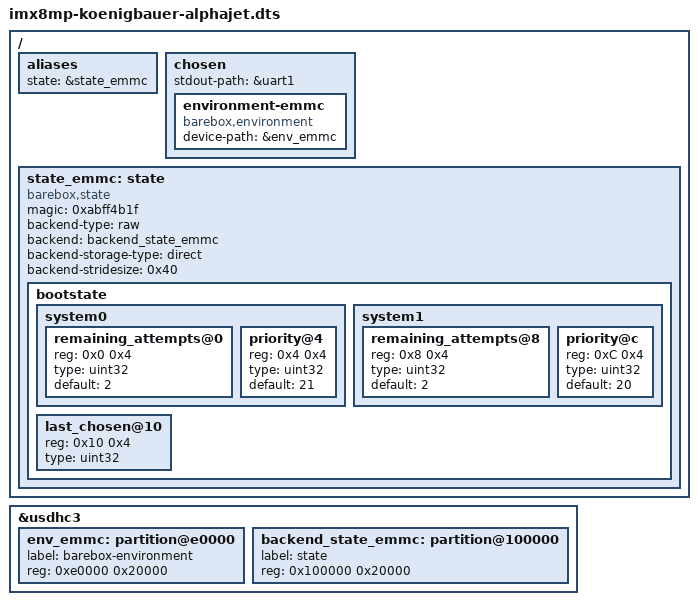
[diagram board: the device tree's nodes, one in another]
// SPDX-License-Identifier: (GPL-2.0+ OR MIT)
// SPDX-FileCopyrightText: 2023 Pengutronix, Johannes Zink <j.zink@pengutronix.de>

#include "imx8mp-koenigbauer-alphajet.kernel.dts"
#include "imx8mp-congatec-qmx8p.dtsi"

/ {
	aliases {
		state = &state_emmc;
	};

	chosen {
		stdout-path = &uart1; /* baseboard UART0, connector J12 */
		environment-emmc {
			compatible = "barebox,environment";
			device-path = &env_emmc;
		};
	};

	state_emmc: state {
		compatible = "barebox,state";
		magic = <0xabff4b1f>;
		backend-type = "raw";
		backend = <&backend_state_emmc>;
		backend-storage-type="direct";
		backend-stridesize = <0x40>;
		#address-cells = <1>;
		#size-cells = <1>;

		bootstate {
			#address-cells = <1>;
			#size-cells = <1>;

			system0 {
				#address-cells = <1>;
				#size-cells = <1>;

				remaining_attempts@0 {
					reg = <0x0 0x4>;
					type = "uint32";
					default = <2>;
				};

				priority@4 {
					reg = <0x4 0x4>;
					type= "uint32";
					default = <21>;
				};
			};

			system1 {
				#address-cells = <1>;
				#size-cells = <1>;

				remaining_attempts@8 {
					reg = <0x8 0x4>;
					type = "uint32";
					default = <2>;
				};

				priority@c {
					reg = <0xC 0x4>;
					type= "uint32";
					default = <20>;
				};
			};

			last_chosen@10 {
				reg = <0x10 0x4>;
				type = "uint32";
			};

		};

	};
};

&usdhc3 { /* on-SoM eMMC */
	#address-cells = <1>;
	#size-cells = <1>;

	env_emmc: partition@e0000 {
		label = "barebox-environment";
		reg = <0xe0000 0x20000>;
	};

	backend_state_emmc: partition@100000 {
		label = "state";
		reg = <0x100000 0x20000>;
	};
};
